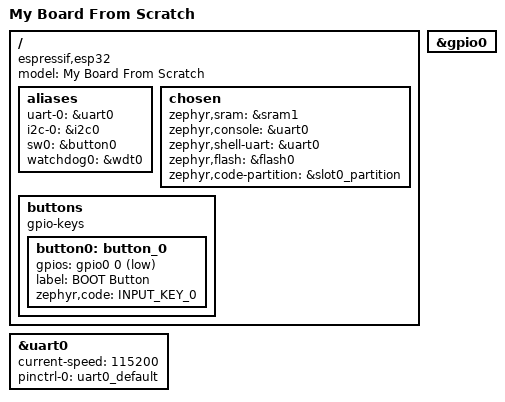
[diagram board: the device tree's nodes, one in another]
/dts-v1/;

#include <espressif/esp32/esp32_wrover_e_n4r8.dtsi>
#include <zephyr/dt-bindings/input/input-event-codes.h>
#include <espressif/partitions_0x1000_amp.dtsi>
#include "esp32_devkitc-pinctrl.dtsi"

/ {
	model = "My Board From Scratch";
	compatible = "espressif,esp32";

    aliases {
		uart-0 = &uart0;
		i2c-0 = &i2c0;
		sw0 = &button0;
		watchdog0 = &wdt0;
	};

    chosen {
		zephyr,sram = &sram1;
		zephyr,console = &uart0;
		zephyr,shell-uart = &uart0;
		zephyr,flash = &flash0;
		zephyr,code-partition = &slot0_partition;
	};

    buttons {
		compatible = "gpio-keys";

		button0: button_0 {
			gpios = <&gpio0 0 (GPIO_PULL_UP | GPIO_ACTIVE_LOW)>;
			label = "BOOT Button";
			zephyr,code = <INPUT_KEY_0>;
		};
	};
};

&uart0 {
	status = "okay";
	current-speed = <115200>;
	pinctrl-0 = <&uart0_default>;
	pinctrl-names = "default";
};

&gpio0 {
	status = "okay";
};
